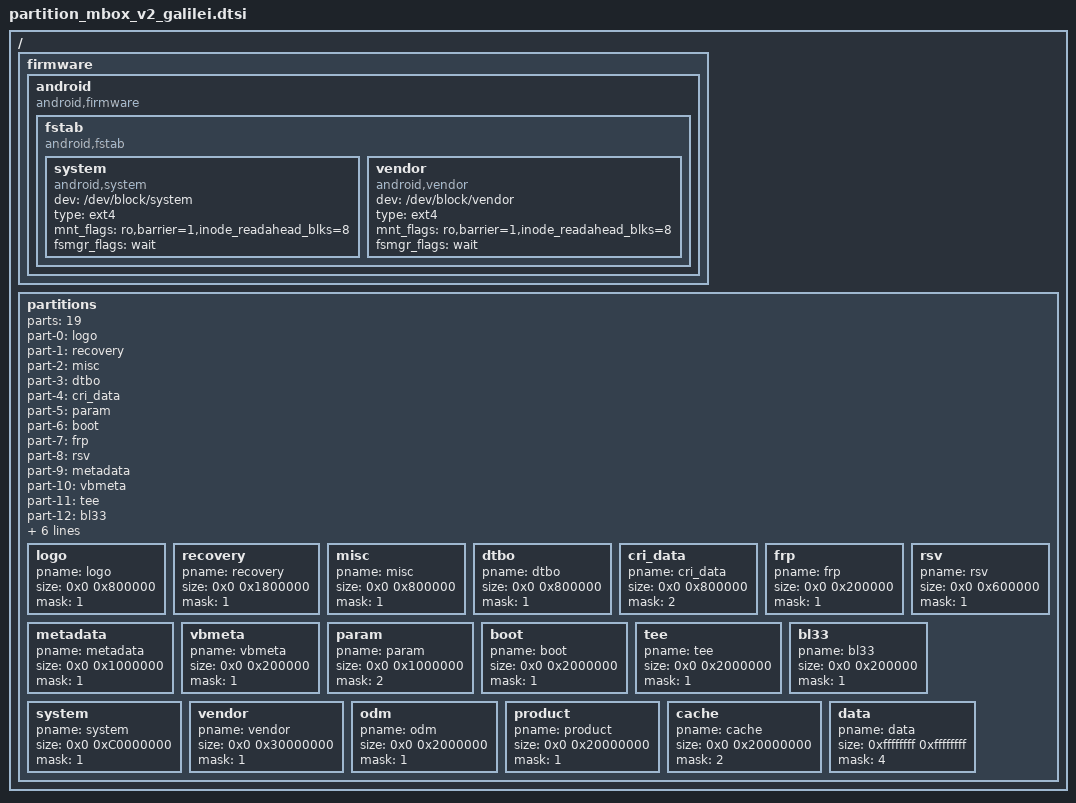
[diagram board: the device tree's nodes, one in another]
/*
 * v2 (64-bit userspace) partition set for Beelink GT-King (galilei).
 *
 * Plain system/vendor/product/odm partitions instead of "super", the layout of voodik's LineageOS 22.1
 * ATV for ODROID-N2 (same S922X): its vendor fstab and first-stage mounts use /dev/block/<name>, and
 * the Amlogic eMMC partition driver (drivers/amlogic/mmc/emmc_partitions.c, present in his kernel)
 * names the partitions from this table. The chain-load part stays as in v1: the stock bootloader's
 * default-env hook reads "bl33" and jumps into the galilei u-boot.
 *
 * Sizes: voodik's system.img is 2560 MiB and vendor.img 512 MiB; both get headroom for our own
 * arm64 builds. Everything else is the v1 (deadpool-derived) layout.
 *
 * This file is licensed under a dual GPLv2 or BSD license.
 */

/ {
	firmware {
		android {
			compatible = "android,firmware";
			fstab {
				compatible = "android,fstab";
				system {
					compatible = "android,system";
					dev = "/dev/block/system";
					type = "ext4";
					mnt_flags = "ro,barrier=1,inode_readahead_blks=8";
					fsmgr_flags = "wait";
				};
				vendor {
					compatible = "android,vendor";
					dev = "/dev/block/vendor";
					type = "ext4";
					mnt_flags = "ro,barrier=1,inode_readahead_blks=8";
					fsmgr_flags = "wait";
				};
			};
		};
	};

	partitions: partitions{
		parts = <19>;
		part-0 = <&logo>;
		part-1 = <&recovery>;
		part-2 = <&misc>;
		part-3 = <&dtbo>;
		part-4 = <&cri_data>;
		part-5 = <&param>;
		part-6 = <&boot>;
		part-7 = <&frp>;
		part-8 = <&rsv>;
		part-9 = <&metadata>;
		part-10 = <&vbmeta>;
		part-11 = <&tee>;
		part-12 = <&bl33>;
		part-13 = <&system>;
		part-14 = <&vendor>;
		part-15 = <&odm>;
		part-16 = <&product>;
		part-17 = <&cache>;
		part-18 = <&data>;

		logo:logo{
			pname = "logo";
			size = <0x0 0x800000>;
			mask = <1>;
		};
		recovery:recovery{
			pname = "recovery";
			size = <0x0 0x1800000>;
			mask = <1>;
		};
		misc:misc{
			pname = "misc";
			size = <0x0 0x800000>;
			mask = <1>;
		};
		dtbo:dtbo{
			pname = "dtbo";
			size = <0x0 0x800000>;
			mask = <1>;
		};
		cri_data:cri_data
		{
			pname = "cri_data";
			size = <0x0 0x800000>;
			mask = <2>;
		};
		frp:frp{
			pname = "frp";
			size = <0x0 0x200000>;
			mask = <1>;
		};
		rsv:rsv{
			pname = "rsv";
			size = <0x0 0x600000>;
			mask = <1>;
		};
		metadata:metadata{
			pname = "metadata";
			size = <0x0 0x1000000>;
			mask = <1>;
		};
		vbmeta:vbmeta{
			pname = "vbmeta";
			size = <0x0 0x200000>;
			mask = <1>;
		};
		param:param{
			pname = "param";
			size = <0x0 0x1000000>;
			mask = <2>;
		};
		boot:boot
		{
			pname = "boot";
			size = <0x0 0x2000000>;
			mask = <1>;
		};
		tee:tee{
			pname = "tee";
			size = <0x0 0x2000000>;
			mask = <1>;
		};
		/* raw galilei u-boot BL33, chainloaded by the stock bootloader's default-env hook */
		bl33:bl33{
			pname = "bl33";
			size = <0x0 0x200000>;
			mask = <1>;
		};
		system:system
		{
			pname = "system";
			size = <0x0 0xC0000000>;	/* 3 GiB */
			mask = <1>;
		};
		vendor:vendor
		{
			pname = "vendor";
			size = <0x0 0x30000000>;	/* 768 MiB */
			mask = <1>;
		};
		odm:odm
		{
			pname = "odm";
			size = <0x0 0x2000000>;		/* 32 MiB */
			mask = <1>;
		};
		product:product
		{
			pname = "product";
			size = <0x0 0x20000000>;	/* 512 MiB */
			mask = <1>;
		};
		cache:cache
		{
			pname = "cache";
			size = <0x0 0x20000000>;	/* 512 MiB */
			mask = <2>;
		};
		data:data
		{
			pname = "data";
			size = <0xffffffff 0xffffffff>;
			mask = <4>;
		};
	};
};/* end of / */
